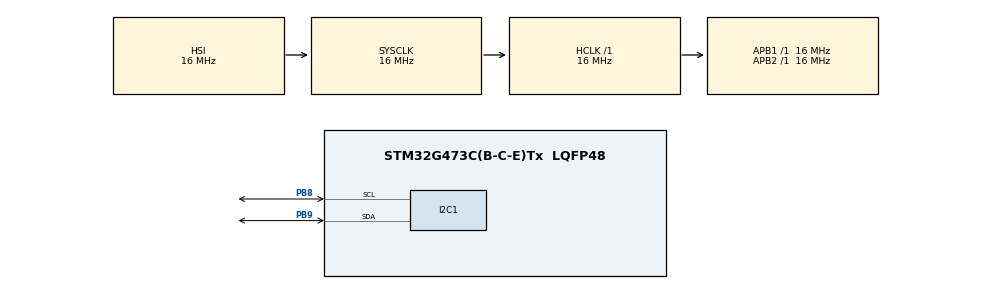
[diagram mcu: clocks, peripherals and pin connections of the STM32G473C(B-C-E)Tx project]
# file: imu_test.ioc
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Mcu.Family=STM32G4
PB8-BOOT0.Mode=I2C
RCC.CortexFreq_Value=16000000
RCC.EXTERNAL_CLOCK_VALUE=12288000
VP_TIM16_VS_ClockSourceINT.Mode=Enable_Timer
ProjectManager.StackSize=0x400
ProjectManager.TargetToolchain=STM32CubeIDE
RCC.HCLKFreq_Value=16000000
PB9.Mode=I2C
RCC.APB2TimFreq_Value=16000000
RCC.USBFreq_Value=64000000
RCC.LSE_VALUE=32768
RCC.AHBFreq_Value=16000000
RCC.HSE_VALUE=8000000
PB8-BOOT0.Signal=I2C1_SCL
board=custom
RCC.VCOOutputFreq_Value=128000000
TIM16.PeriodNoDither=63
RCC.APB2Freq_Value=16000000
VP_SYS_VS_DBSignals.Mode=DisableDeadBatterySignals
Mcu.Name=STM32G473C(B-C-E)Tx
RCC.SYSCLKFreq_VALUE=16000000
PB9.Signal=I2C1_SDA
Mcu.Package=LQFP48
ProjectManager.HeapSize=0x200
RCC.HSI_VALUE=16000000
NVIC.TIM1_UP_TIM16_IRQn=true\:0\:0\:false\:false\:true\:true\:true
NVIC.PriorityGroup=NVIC_PRIORITYGROUP_4
RCC.APB1TimFreq_Value=16000000
TIM16.Prescaler=999
RCC.APB1Freq_Value=16000000
RCC.HSI48_VALUE=48000000

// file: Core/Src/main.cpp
/* USER CODE BEGIN Header */
/**
  ******************************************************************************
  * @file           : main.c
  * @brief          : Main program body
  ******************************************************************************
  * @attention
  *
  * <h2><center>&copy; Copyright (c) 2021 STMicroelectronics.
  * All rights reserved.</center></h2>
  *
  * This software component is licensed by ST under BSD 3-Clause license,
  * the "License"; You may not use this file except in compliance with the
  * License. You may obtain a copy of the License at:
  *                        opensource.org/licenses/BSD-3-Clause
  *
  ******************************************************************************
  */
/* USER CODE END Header */
#include "main.h"

/* USER CODE BEGIN Includes */
#include "kalman.h"
#include "matrix_math.h"
#include "icm42605.h"
/* USER CODE END Includes */

/* USER CODE BEGIN PD */
using namespace std;
int vector_size = 2;			//size of square matrix

float gyro_roll, acc_roll, kalman_roll;		//for debugging
float gyro_pitch, acc_pitch, kalman_pitch;	//for debugging
float variance_pitch;

//Kalman Filter matrices
matrix Q= {{0.005, 0}, {0, 0.005}};					//Process noise covariance matrix
matrix A = {{1, 0}, {0, 1}};						//State transition matrix
matrix B = {{0.004, 0}, {0, 0.004}};				//Control input matrix, dt
matrix x_e = {{10, 0}, {0, 10}};					//initial value
matrix p_e = {{0.10, 0}, {0, 0.10}};				//State error variance
matrix I = {{1, 0}, {0, 1}};						//Identity matrix
matrix H = {{1, 0}, {0, 1}};						//Measurement matrix
matrix R(vector_size , matrix_1D (vector_size, 0));	//Measurement noise matrix
/* USER CODE END PD */

I2C_HandleTypeDef hi2c1;
TIM_HandleTypeDef htim16;

void SystemClock_Config(void);
static void MX_GPIO_Init(void);
static void MX_I2C1_Init(void);
static void MX_TIM16_Init(void);

/* USER CODE BEGIN 0 */
kf_math kf_math;
ICM42605 ICM42605;
Kalman kf(Q, A, B, x_e, p_e, I, H);
/* USER CODE END 0 */

int main(void)
{

  /* MCU Configuration--------------------------------------------------------*/

  /* Reset of all peripherals, Initializes the Flash interface and the Systick. */
  HAL_Init();

  /* Configure the system clock */
  SystemClock_Config();

  /* Initialize all configured peripherals */
  MX_GPIO_Init();
  MX_I2C1_Init();
  MX_TIM16_Init();
  /* USER CODE BEGIN 2 */

  ICM42605.Init();
  ICM42605.GyroCalibrate();

  HAL_TIM_Base_Start_IT(&htim16);
  /* USER CODE END 2 */

  /* Infinite loop */
  while (1)
  {

  }
}

void SystemClock_Config(void)
{
  RCC_OscInitTypeDef RCC_OscInitStruct = {0};
  RCC_ClkInitTypeDef RCC_ClkInitStruct = {0};
  RCC_PeriphCLKInitTypeDef PeriphClkInit = {0};

  /** Configure the main internal regulator output voltage
  */
  HAL_PWREx_ControlVoltageScaling(PWR_REGULATOR_VOLTAGE_SCALE1);
  /** Initializes the RCC Oscillators according to the specified parameters
  * in the RCC_OscInitTypeDef structure.
  */
  RCC_OscInitStruct.OscillatorType = RCC_OSCILLATORTYPE_HSI;
  RCC_OscInitStruct.HSIState = RCC_HSI_ON;
  RCC_OscInitStruct.HSICalibrationValue = RCC_HSICALIBRATION_DEFAULT;
  RCC_OscInitStruct.PLL.PLLState = RCC_PLL_NONE;
  if (HAL_RCC_OscConfig(&RCC_OscInitStruct) != HAL_OK)
  {
    Error_Handler();
  }
  /** Initializes the CPU, AHB and APB buses clocks
  */
  RCC_ClkInitStruct.ClockType = RCC_CLOCKTYPE_HCLK|RCC_CLOCKTYPE_SYSCLK
                              |RCC_CLOCKTYPE_PCLK1|RCC_CLOCKTYPE_PCLK2;
  RCC_ClkInitStruct.SYSCLKSource = RCC_SYSCLKSOURCE_HSI;
  RCC_ClkInitStruct.AHBCLKDivider = RCC_SYSCLK_DIV1;
  RCC_ClkInitStruct.APB1CLKDivider = RCC_HCLK_DIV1;
  RCC_ClkInitStruct.APB2CLKDivider = RCC_HCLK_DIV1;

  if (HAL_RCC_ClockConfig(&RCC_ClkInitStruct, FLASH_LATENCY_0) != HAL_OK)
  {
    Error_Handler();
  }
  /** Initializes the peripherals clocks
  */
  PeriphClkInit.PeriphClockSelection = RCC_PERIPHCLK_I2C1;
  PeriphClkInit.I2c1ClockSelection = RCC_I2C1CLKSOURCE_PCLK1;
  if (HAL_RCCEx_PeriphCLKConfig(&PeriphClkInit) != HAL_OK)
  {
    Error_Handler();
  }
}

static void MX_I2C1_Init(void)
{

  hi2c1.Instance = I2C1;
  hi2c1.Init.Timing = 0x00303D5B;
  hi2c1.Init.OwnAddress1 = 0;
  hi2c1.Init.AddressingMode = I2C_ADDRESSINGMODE_7BIT;
  hi2c1.Init.DualAddressMode = I2C_DUALADDRESS_DISABLE;
  hi2c1.Init.OwnAddress2 = 0;
  hi2c1.Init.OwnAddress2Masks = I2C_OA2_NOMASK;
  hi2c1.Init.GeneralCallMode = I2C_GENERALCALL_DISABLE;
  hi2c1.Init.NoStretchMode = I2C_NOSTRETCH_DISABLE;
  if (HAL_I2C_Init(&hi2c1) != HAL_OK)
  {
    Error_Handler();
  }
  /** Configure Analogue filter
  */
  if (HAL_I2CEx_ConfigAnalogFilter(&hi2c1, I2C_ANALOGFILTER_ENABLE) != HAL_OK)
  {
    Error_Handler();
  }
  /** Configure Digital filter
  */
  if (HAL_I2CEx_ConfigDigitalFilter(&hi2c1, 0) != HAL_OK)
  {
    Error_Handler();
  }

}

static void MX_TIM16_Init(void)
{

  htim16.Instance = TIM16;
  htim16.Init.Prescaler = 999;
  htim16.Init.CounterMode = TIM_COUNTERMODE_UP;
  htim16.Init.Period = 63;
  htim16.Init.ClockDivision = TIM_CLOCKDIVISION_DIV1;
  htim16.Init.RepetitionCounter = 0;
  htim16.Init.AutoReloadPreload = TIM_AUTORELOAD_PRELOAD_DISABLE;
  if (HAL_TIM_Base_Init(&htim16) != HAL_OK)
  {
    Error_Handler();
  }

}

static void MX_GPIO_Init(void)
{

  /* GPIO Ports Clock Enable */
  __HAL_RCC_GPIOB_CLK_ENABLE();

}

/* USER CODE BEGIN 4 */
//Callback: Timer has reset
void HAL_TIM_PeriodElapsedCallback(TIM_HandleTypeDef *htim)
{
	if ((htim == &htim16) && (ICM42605.gyro_calibration_flag_))
	{
		  ICM42605.ReadAcc();
		  ICM42605.ReadGyro();

		  R = {{kf_math.variance(ICM42605.acc_[0][0], 100), 0},
			   {0, kf_math.variance(ICM42605.acc_[1][1], 100)}};

		  kf.Prediction(ICM42605.gyro_);	//Control vector
		  kf.KalmanGain(R);					//Measurement noise vector
		  kf.Update(ICM42605.acc_);

		  //for debugging, print Kalman output, gyro pitch, accelerometer pitch
		  gyro_pitch = ICM42605.gyro_[0][0]*57.296f;
		  acc_pitch = ICM42605.acc_[0][0]*57.296f;
		  kalman_pitch = kf.x_e_[0][0]*57.296f;

		  gyro_roll = ICM42605.gyro_[1][1]*57.296f;
		  acc_roll = ICM42605.acc_[1][1]*57.296f;
		  kalman_roll = kf.x_e_[1][1]*57.296f;
	}
}
/* USER CODE END 4 */

void Error_Handler(void)
{
  __disable_irq();
  while (1)
  {
  }
}

/************************ (C) COPYRIGHT STMicroelectronics *****END OF FILE****/
